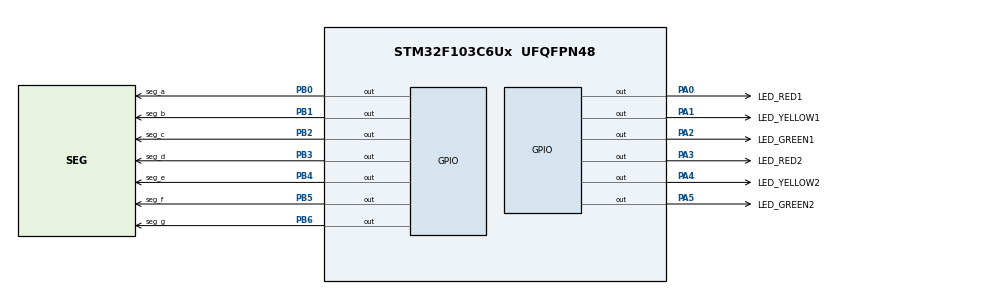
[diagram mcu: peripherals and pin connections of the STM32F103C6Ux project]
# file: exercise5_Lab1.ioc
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Mcu.Family=STM32F1
Mcu.Name=STM32F103C6Ux
Mcu.Package=UFQFPN48
NVIC.PriorityGroup=NVIC_PRIORITYGROUP_4
PA0-WKUP.GPIO_Label=LED_RED1
PA0-WKUP.Signal=GPIO_Output
PA1.GPIO_Label=LED_YELLOW1
PA1.Signal=GPIO_Output
PA2.GPIO_Label=LED_GREEN1
PA2.Signal=GPIO_Output
PA3.GPIO_Label=LED_RED2
PA3.Signal=GPIO_Output
PA4.GPIO_Label=LED_YELLOW2
PA4.Signal=GPIO_Output
PA5.GPIO_Label=LED_GREEN2
PA5.Signal=GPIO_Output
PB0.GPIO_Label=seg_a
PB0.Signal=GPIO_Output
PB1.GPIO_Label=seg_b
PB1.Signal=GPIO_Output
PB2.GPIO_Label=seg_c
PB2.Signal=GPIO_Output
PB3.GPIO_Label=seg_d
PB3.Signal=GPIO_Output
PB4.GPIO_Label=seg_e
PB4.Signal=GPIO_Output
PB5.GPIO_Label=seg_f
PB5.Signal=GPIO_Output
PB6.GPIO_Label=seg_g
PB6.Signal=GPIO_Output
ProjectManager.HeapSize=0x200
ProjectManager.StackSize=0x400
ProjectManager.TargetToolchain=STM32CubeIDE
RCC.APB1Freq_Value=8000000
RCC.APB2Freq_Value=8000000
VP_SYS_VS_ND.Mode=No_Debug
board=custom

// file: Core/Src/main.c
/* USER CODE BEGIN Header */
/**
  ******************************************************************************
  * @file           : main.c
  * @brief          : Main program body
  ******************************************************************************
  * @attention
  *
  * <h2><center>&copy; Copyright (c) 2023 STMicroelectronics.
  * All rights reserved.</center></h2>
  *
  * This software component is licensed by ST under BSD 3-Clause license,
  * the "License"; You may not use this file except in compliance with the
  * License. You may obtain a copy of the License at:
  *                        opensource.org/licenses/BSD-3-Clause
  *
  ******************************************************************************
  */
/* USER CODE END Header */
#include "main.h"

void SystemClock_Config(void);
static void MX_GPIO_Init(void);

int main(void)
{

  /* MCU Configuration--------------------------------------------------------*/

  /* Reset of all peripherals, Initializes the Flash interface and the Systick. */
  HAL_Init();

  /* Configure the system clock */
  SystemClock_Config();

  /* Initialize all configured peripherals */
  MX_GPIO_Init();
  void display7SEG(int num){
    	switch(num){
    	case 0:
    		HAL_GPIO_WritePin(GPIOB,seg_a_Pin,GPIO_PIN_RESET);
    		HAL_GPIO_WritePin(GPIOB,seg_b_Pin,GPIO_PIN_RESET);
    		HAL_GPIO_WritePin(GPIOB,seg_c_Pin,GPIO_PIN_RESET);
    		HAL_GPIO_WritePin(GPIOB,seg_d_Pin,GPIO_PIN_RESET);
    		HAL_GPIO_WritePin(GPIOB,seg_e_Pin,GPIO_PIN_RESET);
    		HAL_GPIO_WritePin(GPIOB,seg_f_Pin,GPIO_PIN_RESET);
    		HAL_GPIO_WritePin(GPIOB,seg_g_Pin,GPIO_PIN_SET);
    		break;
    	case 1:
    		HAL_GPIO_WritePin(GPIOB,seg_a_Pin,GPIO_PIN_SET);
    		HAL_GPIO_WritePin(GPIOB,seg_b_Pin,GPIO_PIN_RESET);
    		HAL_GPIO_WritePin(GPIOB,seg_c_Pin,GPIO_PIN_RESET);
    		HAL_GPIO_WritePin(GPIOB,seg_d_Pin,GPIO_PIN_SET);
    		HAL_GPIO_WritePin(GPIOB,seg_e_Pin,GPIO_PIN_SET);
    		HAL_GPIO_WritePin(GPIOB,seg_f_Pin,GPIO_PIN_SET);
    		HAL_GPIO_WritePin(GPIOB,seg_g_Pin,GPIO_PIN_SET);
    		break;
    	case 2:
    		HAL_GPIO_WritePin(GPIOB,seg_a_Pin,GPIO_PIN_RESET);
    		HAL_GPIO_WritePin(GPIOB,seg_b_Pin,GPIO_PIN_RESET);
    		HAL_GPIO_WritePin(GPIOB,seg_c_Pin,GPIO_PIN_SET);
    		HAL_GPIO_WritePin(GPIOB,seg_d_Pin,GPIO_PIN_RESET);
    		HAL_GPIO_WritePin(GPIOB,seg_e_Pin,GPIO_PIN_RESET);
    		HAL_GPIO_WritePin(GPIOB,seg_f_Pin,GPIO_PIN_SET);
    		HAL_GPIO_WritePin(GPIOB,seg_g_Pin,GPIO_PIN_RESET);
    		break;
    	case 3:
    		HAL_GPIO_WritePin(GPIOB,seg_a_Pin,GPIO_PIN_RESET);
    		HAL_GPIO_WritePin(GPIOB,seg_b_Pin,GPIO_PIN_RESET);
    		HAL_GPIO_WritePin(GPIOB,seg_c_Pin,GPIO_PIN_RESET);
    		HAL_GPIO_WritePin(GPIOB,seg_d_Pin,GPIO_PIN_RESET);
    		HAL_GPIO_WritePin(GPIOB,seg_e_Pin,GPIO_PIN_SET);
    		HAL_GPIO_WritePin(GPIOB,seg_f_Pin,GPIO_PIN_SET);
    		HAL_GPIO_WritePin(GPIOB,seg_g_Pin,GPIO_PIN_RESET);
    		break;
    	case 4:
    		HAL_GPIO_WritePin(GPIOB,seg_a_Pin,GPIO_PIN_SET);
    		HAL_GPIO_WritePin(GPIOB,seg_b_Pin,GPIO_PIN_RESET);
    		HAL_GPIO_WritePin(GPIOB,seg_c_Pin,GPIO_PIN_RESET);
    		HAL_GPIO_WritePin(GPIOB,seg_d_Pin,GPIO_PIN_SET);
    		HAL_GPIO_WritePin(GPIOB,seg_e_Pin,GPIO_PIN_SET);
    		HAL_GPIO_WritePin(GPIOB,seg_f_Pin,GPIO_PIN_RESET);
    		HAL_GPIO_WritePin(GPIOB,seg_g_Pin,GPIO_PIN_RESET);
    		break;
    	case 5:
    		HAL_GPIO_WritePin(GPIOB,seg_a_Pin,GPIO_PIN_RESET);
    		HAL_GPIO_WritePin(GPIOB,seg_b_Pin,GPIO_PIN_SET);
    		HAL_GPIO_WritePin(GPIOB,seg_c_Pin,GPIO_PIN_RESET);
    		HAL_GPIO_WritePin(GPIOB,seg_d_Pin,GPIO_PIN_RESET);
    		HAL_GPIO_WritePin(GPIOB,seg_e_Pin,GPIO_PIN_SET);
    		HAL_GPIO_WritePin(GPIOB,seg_f_Pin,GPIO_PIN_RESET);
    		HAL_GPIO_WritePin(GPIOB,seg_g_Pin,GPIO_PIN_RESET);
    		break;
    	case 6:
    		HAL_GPIO_WritePin(GPIOB,seg_a_Pin,GPIO_PIN_RESET);
    		HAL_GPIO_WritePin(GPIOB,seg_b_Pin,GPIO_PIN_SET);
    		HAL_GPIO_WritePin(GPIOB,seg_c_Pin,GPIO_PIN_RESET);
    		HAL_GPIO_WritePin(GPIOB,seg_d_Pin,GPIO_PIN_RESET);
    		HAL_GPIO_WritePin(GPIOB,seg_e_Pin,GPIO_PIN_RESET);
    		HAL_GPIO_WritePin(GPIOB,seg_f_Pin,GPIO_PIN_RESET);
    		HAL_GPIO_WritePin(GPIOB,seg_g_Pin,GPIO_PIN_RESET);
    		break;
    	case 7:
    		HAL_GPIO_WritePin(GPIOB,seg_a_Pin,GPIO_PIN_RESET);
    		HAL_GPIO_WritePin(GPIOB,seg_b_Pin,GPIO_PIN_RESET);
    		HAL_GPIO_WritePin(GPIOB,seg_c_Pin,GPIO_PIN_RESET);
    		HAL_GPIO_WritePin(GPIOB,seg_d_Pin,GPIO_PIN_SET);
    		HAL_GPIO_WritePin(GPIOB,seg_e_Pin,GPIO_PIN_SET);
    		HAL_GPIO_WritePin(GPIOB,seg_f_Pin,GPIO_PIN_SET);
    		HAL_GPIO_WritePin(GPIOB,seg_g_Pin,GPIO_PIN_SET);
    		break;
    	case 8:
    		HAL_GPIO_WritePin(GPIOB,seg_a_Pin,GPIO_PIN_RESET);
    		HAL_GPIO_WritePin(GPIOB,seg_b_Pin,GPIO_PIN_RESET);
    		HAL_GPIO_WritePin(GPIOB,seg_c_Pin,GPIO_PIN_RESET);
    		HAL_GPIO_WritePin(GPIOB,seg_d_Pin,GPIO_PIN_RESET);
    		HAL_GPIO_WritePin(GPIOB,seg_e_Pin,GPIO_PIN_RESET);
    		HAL_GPIO_WritePin(GPIOB,seg_f_Pin,GPIO_PIN_RESET);
    		HAL_GPIO_WritePin(GPIOB,seg_g_Pin,GPIO_PIN_RESET);
    		break;
    	case 9:
    		HAL_GPIO_WritePin(GPIOB,seg_a_Pin,GPIO_PIN_RESET);
    		HAL_GPIO_WritePin(GPIOB,seg_b_Pin,GPIO_PIN_RESET);
    		HAL_GPIO_WritePin(GPIOB,seg_c_Pin,GPIO_PIN_RESET);
    		HAL_GPIO_WritePin(GPIOB,seg_d_Pin,GPIO_PIN_RESET);
    		HAL_GPIO_WritePin(GPIOB,seg_e_Pin,GPIO_PIN_SET);
    		HAL_GPIO_WritePin(GPIOB,seg_f_Pin,GPIO_PIN_RESET);
    		HAL_GPIO_WritePin(GPIOB,seg_g_Pin,GPIO_PIN_RESET);
    		break;
    	}
    }
  void RED1andGREEN2(){
  	  HAL_GPIO_WritePin(GPIOA, LED_RED1_Pin, GPIO_PIN_RESET);
  	  HAL_GPIO_WritePin(GPIOA, LED_YELLOW1_Pin, GPIO_PIN_SET);
  	  HAL_GPIO_WritePin(GPIOA, LED_GREEN1_Pin, GPIO_PIN_SET);
  	  HAL_GPIO_WritePin(GPIOA, LED_RED2_Pin, GPIO_PIN_SET);
  	  HAL_GPIO_WritePin(GPIOA, LED_YELLOW2_Pin, GPIO_PIN_SET);
  	  HAL_GPIO_WritePin(GPIOA, LED_GREEN2_Pin, GPIO_PIN_RESET);
    }
    void RED1andYELLOW2(){
  	  HAL_GPIO_WritePin(GPIOA, LED_RED1_Pin, GPIO_PIN_RESET);
  	  HAL_GPIO_WritePin(GPIOA, LED_YELLOW1_Pin, GPIO_PIN_SET);
  	  HAL_GPIO_WritePin(GPIOA, LED_GREEN1_Pin, GPIO_PIN_SET);
  	  HAL_GPIO_WritePin(GPIOA, LED_RED2_Pin, GPIO_PIN_SET);
  	  HAL_GPIO_WritePin(GPIOA, LED_YELLOW2_Pin, GPIO_PIN_RESET);
  	  HAL_GPIO_WritePin(GPIOA, LED_GREEN2_Pin, GPIO_PIN_SET);
    }
    void GREEN1andRED2(){
  	  HAL_GPIO_WritePin(GPIOA, LED_RED1_Pin, GPIO_PIN_SET);
  	  HAL_GPIO_WritePin(GPIOA, LED_YELLOW1_Pin, GPIO_PIN_SET);
  	  HAL_GPIO_WritePin(GPIOA, LED_GREEN1_Pin, GPIO_PIN_RESET);
  	  HAL_GPIO_WritePin(GPIOA, LED_RED2_Pin, GPIO_PIN_RESET);
  	  HAL_GPIO_WritePin(GPIOA, LED_YELLOW2_Pin, GPIO_PIN_SET);
  	  HAL_GPIO_WritePin(GPIOA, LED_GREEN2_Pin, GPIO_PIN_SET);
    }
    void YELLOW1andRED2(){
  	  HAL_GPIO_WritePin(GPIOA, LED_RED1_Pin, GPIO_PIN_SET);
  	  HAL_GPIO_WritePin(GPIOA, LED_YELLOW1_Pin, GPIO_PIN_RESET);
  	  HAL_GPIO_WritePin(GPIOA, LED_GREEN1_Pin, GPIO_PIN_SET);
  	  HAL_GPIO_WritePin(GPIOA, LED_RED2_Pin, GPIO_PIN_RESET);
  	  HAL_GPIO_WritePin(GPIOA, LED_YELLOW2_Pin, GPIO_PIN_SET);
  	  HAL_GPIO_WritePin(GPIOA, LED_GREEN2_Pin, GPIO_PIN_SET);
    }
  /* Infinite loop */
  /* USER CODE BEGIN WHILE */
    int count=0;
    int next_status=0;
  while (1)
  {
    /* USER CODE END WHILE */
	  		  switch(next_status){
	  		  	  case 0:
	  		  		  RED1andGREEN2();
	  		  		  next_status=1;
	  		  		  count=3;
	  		  		  break;
	  		  	  case 1:
	  		  	  	  RED1andYELLOW2();
	  		  		  next_status=2;
	  		  		  count=2;
	  		  		  break;
	  		  	  case 2:
	  		  		  GREEN1andRED2();
	  		  		  next_status=3;
	  		  		  count=3;
	  		  		  break;
	  		  	  case 3:
	  		  		  YELLOW1andRED2();
	  		  		  next_status=0;
	  		  		  count=2;
	  		  		  break;
	  		  }
	  	  for(int i=count;i>0;i--){
	  		  display7SEG(i);
	  		  HAL_Delay(1000);
	  	  }
  }
}

void SystemClock_Config(void)
{
  RCC_OscInitTypeDef RCC_OscInitStruct = {0};
  RCC_ClkInitTypeDef RCC_ClkInitStruct = {0};

  /** Initializes the RCC Oscillators according to the specified parameters
  * in the RCC_OscInitTypeDef structure.
  */
  RCC_OscInitStruct.OscillatorType = RCC_OSCILLATORTYPE_HSI;
  RCC_OscInitStruct.HSIState = RCC_HSI_ON;
  RCC_OscInitStruct.HSICalibrationValue = RCC_HSICALIBRATION_DEFAULT;
  RCC_OscInitStruct.PLL.PLLState = RCC_PLL_NONE;
  if (HAL_RCC_OscConfig(&RCC_OscInitStruct) != HAL_OK)
  {
    Error_Handler();
  }
  /** Initializes the CPU, AHB and APB buses clocks
  */
  RCC_ClkInitStruct.ClockType = RCC_CLOCKTYPE_HCLK|RCC_CLOCKTYPE_SYSCLK
                              |RCC_CLOCKTYPE_PCLK1|RCC_CLOCKTYPE_PCLK2;
  RCC_ClkInitStruct.SYSCLKSource = RCC_SYSCLKSOURCE_HSI;
  RCC_ClkInitStruct.AHBCLKDivider = RCC_SYSCLK_DIV1;
  RCC_ClkInitStruct.APB1CLKDivider = RCC_HCLK_DIV1;
  RCC_ClkInitStruct.APB2CLKDivider = RCC_HCLK_DIV1;

  if (HAL_RCC_ClockConfig(&RCC_ClkInitStruct, FLASH_LATENCY_0) != HAL_OK)
  {
    Error_Handler();
  }
}

static void MX_GPIO_Init(void)
{
  GPIO_InitTypeDef GPIO_InitStruct = {0};

  /* GPIO Ports Clock Enable */
  __HAL_RCC_GPIOA_CLK_ENABLE();
  __HAL_RCC_GPIOB_CLK_ENABLE();

  /*Configure GPIO pin Output Level */
  HAL_GPIO_WritePin(GPIOA, LED_RED1_Pin|LED_YELLOW1_Pin|LED_GREEN1_Pin|LED_RED2_Pin
                          |LED_YELLOW2_Pin|LED_GREEN2_Pin, GPIO_PIN_RESET);

  /*Configure GPIO pin Output Level */
  HAL_GPIO_WritePin(GPIOB, seg_a_Pin|seg_b_Pin|seg_c_Pin|seg_d_Pin
                          |seg_e_Pin|seg_f_Pin|seg_g_Pin, GPIO_PIN_RESET);

  /*Configure GPIO pins : LED_RED1_Pin LED_YELLOW1_Pin LED_GREEN1_Pin LED_RED2_Pin
                           LED_YELLOW2_Pin LED_GREEN2_Pin */
  GPIO_InitStruct.Pin = LED_RED1_Pin|LED_YELLOW1_Pin|LED_GREEN1_Pin|LED_RED2_Pin
                          |LED_YELLOW2_Pin|LED_GREEN2_Pin;
  GPIO_InitStruct.Mode = GPIO_MODE_OUTPUT_PP;
  GPIO_InitStruct.Pull = GPIO_NOPULL;
  GPIO_InitStruct.Speed = GPIO_SPEED_FREQ_LOW;
  HAL_GPIO_Init(GPIOA, &GPIO_InitStruct);

  /*Configure GPIO pins : seg_a_Pin seg_b_Pin seg_c_Pin seg_d_Pin
                           seg_e_Pin seg_f_Pin seg_g_Pin */
  GPIO_InitStruct.Pin = seg_a_Pin|seg_b_Pin|seg_c_Pin|seg_d_Pin
                          |seg_e_Pin|seg_f_Pin|seg_g_Pin;
  GPIO_InitStruct.Mode = GPIO_MODE_OUTPUT_PP;
  GPIO_InitStruct.Pull = GPIO_NOPULL;
  GPIO_InitStruct.Speed = GPIO_SPEED_FREQ_LOW;
  HAL_GPIO_Init(GPIOB, &GPIO_InitStruct);

}

void Error_Handler(void)
{
  __disable_irq();
  while (1)
  {
  }
}

/************************ (C) COPYRIGHT STMicroelectronics *****END OF FILE****/
